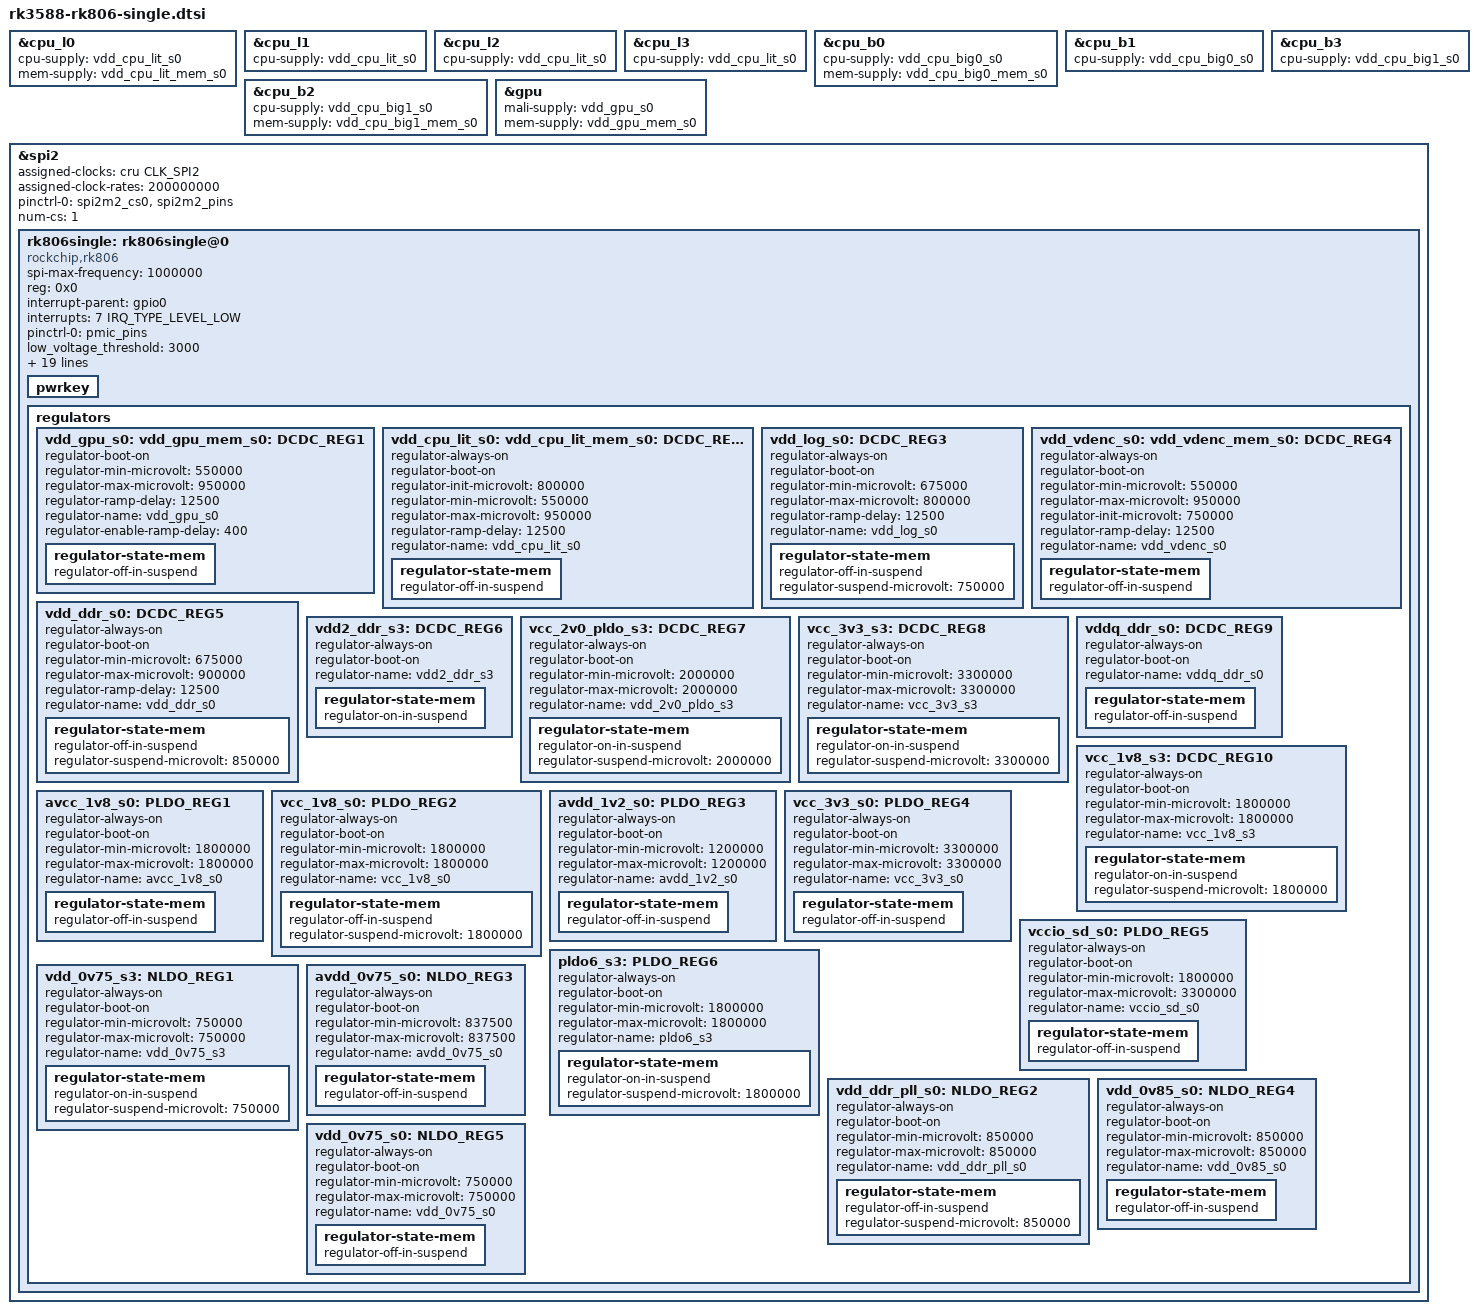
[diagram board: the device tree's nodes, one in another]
// SPDX-License-Identifier: (GPL-2.0+ OR MIT)
/*
 * Copyright (c) 2021 Rockchip Electronics Co., Ltd.
 *
 */

#include <dt-bindings/gpio/gpio.h>
#include <dt-bindings/pinctrl/rockchip.h>

&cpu_l0 {
	cpu-supply = <&vdd_cpu_lit_s0>;
	mem-supply = <&vdd_cpu_lit_mem_s0>;
};

&cpu_l1 {
	cpu-supply = <&vdd_cpu_lit_s0>;
};

&cpu_l2 {
	cpu-supply = <&vdd_cpu_lit_s0>;
};

&cpu_l3 {
	cpu-supply = <&vdd_cpu_lit_s0>;
};

&cpu_b0 {
	cpu-supply = <&vdd_cpu_big0_s0>;
	mem-supply = <&vdd_cpu_big0_mem_s0>;
};

&cpu_b1 {
	cpu-supply = <&vdd_cpu_big0_s0>;
};

&cpu_b2 {
	cpu-supply = <&vdd_cpu_big1_s0>;
	mem-supply = <&vdd_cpu_big1_mem_s0>;
};

&cpu_b3 {
	cpu-supply = <&vdd_cpu_big1_s0>;
};

&gpu {
	mali-supply = <&vdd_gpu_s0>;
	mem-supply = <&vdd_gpu_mem_s0>;
};

&spi2 {
	status = "okay";
	assigned-clocks = <&cru CLK_SPI2>;
	assigned-clock-rates = <200000000>;
	pinctrl-names = "default";
	pinctrl-0 = <&spi2m2_cs0 &spi2m2_pins>;
	num-cs = <1>;

	rk806single: rk806single@0 {
		compatible = "rockchip,rk806";
		spi-max-frequency = <1000000>;
		reg = <0x0>;

		interrupt-parent = <&gpio0>;
		interrupts = <7 IRQ_TYPE_LEVEL_LOW>;

		pinctrl-names = "default";
		pinctrl-0 = <&pmic_pins>;

		/* 2800mv-3500mv */
		low_voltage_threshold = <3000>;
		/* 2700mv-3400mv */
		shutdown_voltage_threshold = <2700>;
		/* 140 160 */
		shutdown_temperture_threshold = <160>;
		hotdie_temperture_threshold = <115>;

		/* 0: restart PMU;
		 * 1: reset all the power off reset registers,
		 *    forcing the state to switch to ACTIVE mode;
		 * 2: Reset all the power off reset registers,
		 *    forcing the state to switch to ACTIVE mode,
		 *    and simultaneously pull down the RESETB PIN for 5mS before releasing
		 */
		pmic-reset-func = <1>;

		vcc1-supply = <&vcc5v0_sys>;
		vcc2-supply = <&vcc5v0_sys>;
		vcc3-supply = <&vcc5v0_sys>;
		vcc4-supply = <&vcc5v0_sys>;
		vcc5-supply = <&vcc5v0_sys>;
		vcc6-supply = <&vcc5v0_sys>;
		vcc7-supply = <&vcc5v0_sys>;
		vcc8-supply = <&vcc5v0_sys>;
		vcc9-supply = <&vcc5v0_sys>;
		vcc10-supply = <&vcc5v0_sys>;
		vcc11-supply = <&vcc_2v0_pldo_s3>;
		vcc12-supply = <&vcc5v0_sys>;
		vcc13-supply = <&vcc_1v1_nldo_s3>;
		vcc14-supply = <&vcc_1v1_nldo_s3>;
		vcca-supply = <&vcc5v0_sys>;

		pwrkey {
			status = "okay";
		};

		regulators {
			vdd_gpu_s0: vdd_gpu_mem_s0: DCDC_REG1 {
				regulator-boot-on;
				regulator-min-microvolt = <550000>;
				regulator-max-microvolt = <950000>;
				regulator-ramp-delay = <12500>;
				regulator-name = "vdd_gpu_s0";
				regulator-enable-ramp-delay = <400>;
				regulator-state-mem {
					regulator-off-in-suspend;
				};
			};

			vdd_cpu_lit_s0: vdd_cpu_lit_mem_s0: DCDC_REG2 {
				regulator-always-on;
				regulator-boot-on;
				regulator-init-microvolt = <800000>;
				regulator-min-microvolt = <550000>;
				regulator-max-microvolt = <950000>;
				regulator-ramp-delay = <12500>;
				regulator-name = "vdd_cpu_lit_s0";
				regulator-state-mem {
					regulator-off-in-suspend;
				};
			};

			vdd_log_s0: DCDC_REG3 {
				regulator-always-on;
				regulator-boot-on;
				regulator-min-microvolt = <675000>;
				regulator-max-microvolt = <800000>;
				regulator-ramp-delay = <12500>;
				regulator-name = "vdd_log_s0";
				regulator-state-mem {
					regulator-off-in-suspend;
					regulator-suspend-microvolt = <750000>;
				};
			};

			vdd_vdenc_s0: vdd_vdenc_mem_s0: DCDC_REG4 {
				regulator-always-on;
				regulator-boot-on;
				regulator-min-microvolt = <550000>;
				regulator-max-microvolt = <950000>;
				regulator-init-microvolt = <750000>;
				regulator-ramp-delay = <12500>;
				regulator-name = "vdd_vdenc_s0";
				regulator-state-mem {
					regulator-off-in-suspend;
				};
			};

			vdd_ddr_s0: DCDC_REG5 {
				regulator-always-on;
				regulator-boot-on;
				regulator-min-microvolt = <675000>;
				regulator-max-microvolt = <900000>;
				regulator-ramp-delay = <12500>;
				regulator-name = "vdd_ddr_s0";
				regulator-state-mem {
					regulator-off-in-suspend;
					regulator-suspend-microvolt = <850000>;
				};
			};

			vdd2_ddr_s3: DCDC_REG6 {
				regulator-always-on;
				regulator-boot-on;
				regulator-name = "vdd2_ddr_s3";
				regulator-state-mem {
					regulator-on-in-suspend;
				};
			};

			vcc_2v0_pldo_s3: DCDC_REG7 {
				regulator-always-on;
				regulator-boot-on;
				regulator-min-microvolt = <2000000>;
				regulator-max-microvolt = <2000000>;
				regulator-name = "vdd_2v0_pldo_s3";
				regulator-state-mem {
					regulator-on-in-suspend;
					regulator-suspend-microvolt = <2000000>;
				};
			};

			vcc_3v3_s3: DCDC_REG8 {
				regulator-always-on;
				regulator-boot-on;
				regulator-min-microvolt = <3300000>;
				regulator-max-microvolt = <3300000>;
				regulator-name = "vcc_3v3_s3";
				regulator-state-mem {
					regulator-on-in-suspend;
					regulator-suspend-microvolt = <3300000>;
				};
			};

			vddq_ddr_s0: DCDC_REG9 {
				regulator-always-on;
				regulator-boot-on;
				regulator-name = "vddq_ddr_s0";
				regulator-state-mem {
					regulator-off-in-suspend;
				};
			};

			vcc_1v8_s3: DCDC_REG10 {
				regulator-always-on;
				regulator-boot-on;
				regulator-min-microvolt = <1800000>;
				regulator-max-microvolt = <1800000>;
				regulator-name = "vcc_1v8_s3";
				regulator-state-mem {
					regulator-on-in-suspend;
					regulator-suspend-microvolt = <1800000>;
				};
			};

			avcc_1v8_s0: PLDO_REG1 {
				regulator-always-on;
				regulator-boot-on;
				regulator-min-microvolt = <1800000>;
				regulator-max-microvolt = <1800000>;
				regulator-name = "avcc_1v8_s0";
				regulator-state-mem {
					regulator-off-in-suspend;
				};
			};

			vcc_1v8_s0: PLDO_REG2 {
				regulator-always-on;
				regulator-boot-on;
				regulator-min-microvolt = <1800000>;
				regulator-max-microvolt = <1800000>;
				regulator-name = "vcc_1v8_s0";
				regulator-state-mem {
					regulator-off-in-suspend;
					regulator-suspend-microvolt = <1800000>;
				};
			};

			avdd_1v2_s0: PLDO_REG3 {
				regulator-always-on;
				regulator-boot-on;
				regulator-min-microvolt = <1200000>;
				regulator-max-microvolt = <1200000>;
				regulator-name = "avdd_1v2_s0";
				regulator-state-mem {
					regulator-off-in-suspend;
				};
			};

			vcc_3v3_s0: PLDO_REG4 {
				regulator-always-on;
				regulator-boot-on;
				regulator-min-microvolt = <3300000>;
				regulator-max-microvolt = <3300000>;
				regulator-name = "vcc_3v3_s0";
				regulator-state-mem {
					regulator-off-in-suspend;
				};
			};

			vccio_sd_s0: PLDO_REG5 {
				regulator-always-on;
				regulator-boot-on;
				regulator-min-microvolt = <1800000>;
				regulator-max-microvolt = <3300000>;
				regulator-name = "vccio_sd_s0";
				regulator-state-mem {
					regulator-off-in-suspend;
				};
			};

			pldo6_s3: PLDO_REG6 {
				regulator-always-on;
				regulator-boot-on;
				regulator-min-microvolt = <1800000>;
				regulator-max-microvolt = <1800000>;
				regulator-name = "pldo6_s3";
				regulator-state-mem {
					regulator-on-in-suspend;
					regulator-suspend-microvolt = <1800000>;
				};
			};

			vdd_0v75_s3: NLDO_REG1 {
				regulator-always-on;
				regulator-boot-on;
				regulator-min-microvolt = <750000>;
				regulator-max-microvolt = <750000>;
				regulator-name = "vdd_0v75_s3";
				regulator-state-mem {
					regulator-on-in-suspend;
					regulator-suspend-microvolt = <750000>;
				};
			};

			vdd_ddr_pll_s0: NLDO_REG2 {
				regulator-always-on;
				regulator-boot-on;
				regulator-min-microvolt = <850000>;
				regulator-max-microvolt = <850000>;
				regulator-name = "vdd_ddr_pll_s0";
				regulator-state-mem {
					regulator-off-in-suspend;
					regulator-suspend-microvolt = <850000>;
				};
			};

			avdd_0v75_s0: NLDO_REG3 {
				regulator-always-on;
				regulator-boot-on;
				regulator-min-microvolt = <837500>;
				regulator-max-microvolt = <837500>;
				regulator-name = "avdd_0v75_s0";
				regulator-state-mem {
					regulator-off-in-suspend;
				};
			};

			vdd_0v85_s0: NLDO_REG4 {
				regulator-always-on;
				regulator-boot-on;
				regulator-min-microvolt = <850000>;
				regulator-max-microvolt = <850000>;
				regulator-name = "vdd_0v85_s0";
				regulator-state-mem {
					regulator-off-in-suspend;
				};
			};

			vdd_0v75_s0: NLDO_REG5 {
				regulator-always-on;
				regulator-boot-on;
				regulator-min-microvolt = <750000>;
				regulator-max-microvolt = <750000>;
				regulator-name = "vdd_0v75_s0";
				regulator-state-mem {
					regulator-off-in-suspend;
				};
			};
		};
	};
};
